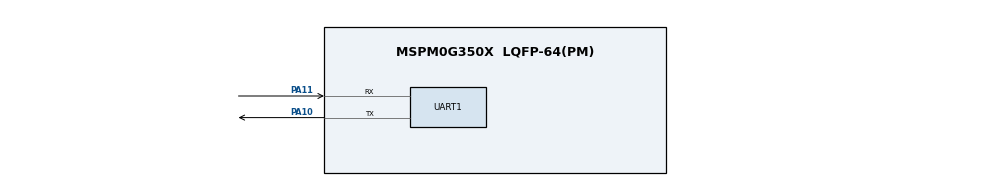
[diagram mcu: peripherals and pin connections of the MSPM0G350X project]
/**
 * @cliArgs --device "MSPM0G350X" --part "Default" --package "LQFP-64(PM)" --product "mspm0_sdk@2.10.00.04"
 * @versions {"tool":"1.27.0+4565"}
 */

/**
 * Import the modules used in this configuration.
 */
const ADC12  = scripting.addModule("/ti/driverlib/ADC12", {}, false);
const ADC121 = ADC12.addInstance();
const SYSCTL = scripting.addModule("/ti/driverlib/SYSCTL");
const UART   = scripting.addModule("/ti/driverlib/UART", {}, false);
const UART1  = UART.addInstance();

/**
 * Write custom configuration values to the imported modules.
 */
ADC121.sampClkDiv                        = "DL_ADC12_CLOCK_DIVIDE_8";
ADC121.adcMem0_name                      = "CH0";
ADC121.powerDownMode                     = "DL_ADC12_POWER_DOWN_MODE_MANUAL";
ADC121.sampleTime0                       = "1 ms";
ADC121.sampleMode                        = "DL_ADC12_SAMPLING_SOURCE_MANUAL";
ADC121.$name                             = "ADC0";
ADC121.peripheral.$assign                = "ADC0";
ADC121.peripheral.adcPin0.$assign        = "PA27";
ADC121.adcPin0Config.$name               = "ti_driverlib_gpio_GPIOPinGeneric0";
ADC121.adcPin0Config.hideOutputInversion = scripting.forceWrite(false);

const Board = scripting.addModule("/ti/driverlib/Board", {}, false);

SYSCTL.forceDefaultClkConfig = true;

UART1.$name                    = "UART_0";
UART1.peripheral.$assign       = "UART0";
UART1.peripheral.rxPin.$assign = "PA11";
UART1.peripheral.txPin.$assign = "PA10";
UART1.txPinConfig.$name        = "ti_driverlib_gpio_GPIOPinGeneric1";
UART1.rxPinConfig.$name        = "ti_driverlib_gpio_GPIOPinGeneric2";

/**
 * Pinmux solution for unlocked pins/peripherals. This ensures that minor changes to the automatic solver in a future
 * version of the tool will not impact the pinmux you originally saw.  These lines can be completely deleted in order to
 * re-solve from scratch.
 */
Board.peripheral.$suggestSolution          = "DEBUGSS";
Board.peripheral.swclkPin.$suggestSolution = "PA20";
Board.peripheral.swdioPin.$suggestSolution = "PA19";
SYSCTL.peripheral.$suggestSolution         = "SYSCTL";
